# HC32F448 register map
File version: 1.0
CPU: CM4 r0p1, little endian, MPU, FPU, 4 interrupt priority bits
Registers are 32-bit, read-write, reset 0x0 unless marked. A register's access mark holds for its fields unless they carry their own. Offsets are from the block's base; [hi:lo] are bit positions; {n}, {i} and the like mark numbered series.

## TMR6CR
Base 0x4003C000; alternate view of TMR61
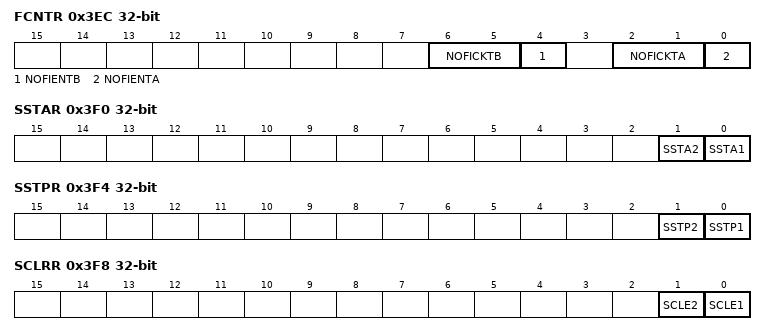
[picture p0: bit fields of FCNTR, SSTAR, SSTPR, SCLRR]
0x3EC FCNTR
  [6:5] NOFICKTB, [4] NOFIENTB, [2:1] NOFICKTA, [0] NOFIENTA
0x3F0 SSTAR
  [1] SSTA2, [0] SSTA1
0x3F4 SSTPR
  [1] SSTP2, [0] SSTP1
0x3F8 SCLRR
  [1] SCLE2, [0] SCLE1
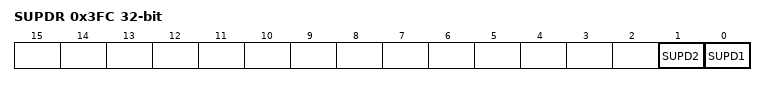
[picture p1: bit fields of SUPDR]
0x3FC SUPDR
  [1] SUPD2, [0] SUPD1

## TMRA1 — desc TMRA
Base 0x4003A000
Same registers: TMRA5 0x40026000, TMRA2 0x4003A400, TMRA3 0x4003A800, TMRA4 0x4003AC00
0x00 CNTER
  [31:0] CNT
0x04 PERAR reset 0xFFFFFFFF
  [31:0] PER
{0x3C+4i} CMPAR{i} reset 0xFFFFFFFF (i=1..8)
  [31:0] CMP
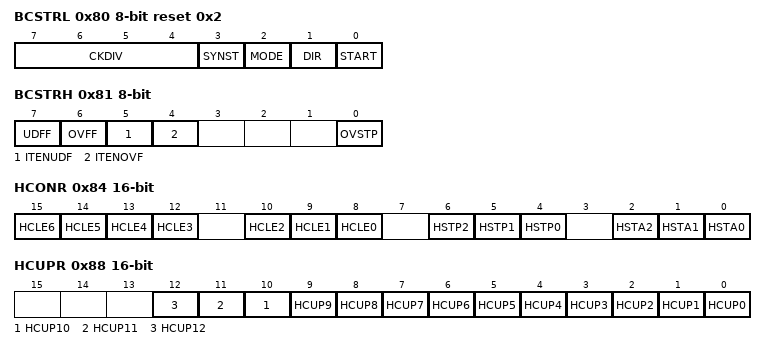
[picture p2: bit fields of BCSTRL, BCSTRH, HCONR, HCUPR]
0x80 BCSTRL 8-bit reset 0x2
  [7:4] CKDIV, [3] SYNST, [2] MODE, [1] DIR, [0] START
0x81 BCSTRH 8-bit
  [7] UDFF, [6] OVFF, [5] ITENUDF, [4] ITENOVF, [0] OVSTP
0x84 HCONR 16-bit
  [n+9] HCLE{n} (n=3..6), [10] HCLE2, [9] HCLE1, [8] HCLE0, [6] HSTP2, [5] HSTP1, [4] HSTP0, [2] HSTA2, [1] HSTA1, [0] HSTA0
0x88 HCUPR 16-bit
  [n] HCUP{n} (n=0..12)
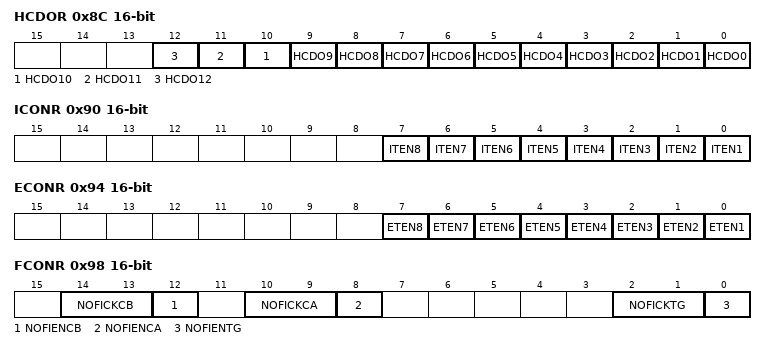
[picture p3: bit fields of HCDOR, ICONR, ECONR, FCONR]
0x8C HCDOR 16-bit
  [n] HCDO{n} (n=0..12)
0x90 ICONR 16-bit
  [n-1] ITEN{n} (n=1..8)
0x94 ECONR 16-bit
  [n-1] ETEN{n} (n=1..8)
0x98 FCONR 16-bit
  [14:13] NOFICKCB, [12] NOFIENCB, [10:9] NOFICKCA, [8] NOFIENCA, [2:1] NOFICKTG, [0] NOFIENTG
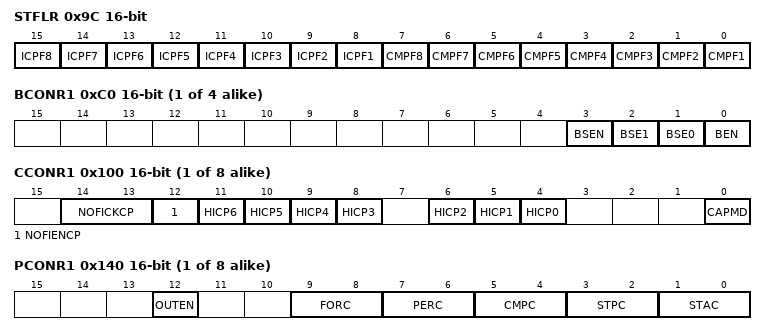
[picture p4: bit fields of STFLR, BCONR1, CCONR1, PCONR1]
0x9C STFLR 16-bit
  [n+7] ICPF{n} (n=1..8), [n-1] CMPF{n} (n=1..8)
{0xB8+8i} BCONR{i} 16-bit (i=1..4)
  [3] BSEN, [2] BSE1, [1] BSE0, [0] BEN
{0xFC+4i} CCONR{i} 16-bit (i=1..8)
  [14:13] NOFICKCP, [12] NOFIENCP, [n+5] HICP{n} (n=3..6), [6] HICP2, [5] HICP1, [4] HICP0, [0] CAPMD
{0x13C+4i} PCONR{i} 16-bit (i=1..8)
  [12] OUTEN, [9:8] FORC, [7:6] PERC, [5:4] CMPC, [3:2] STPC, [1:0] STAC

## TRNG
Base 0x40042000
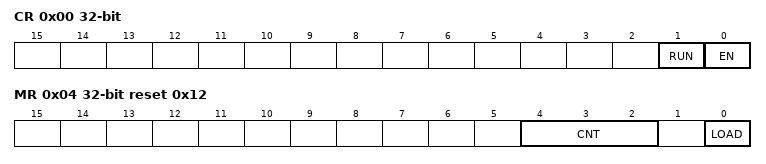
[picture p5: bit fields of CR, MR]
0x00 CR
  [1] RUN, [0] EN
0x04 MR reset 0x12
  [4:2] CNT, [0] LOAD
0x0C DR0 ro
0x10 DR1 ro

## USART1 — desc USART
Base 0x4001CC00
Same registers: USART2 0x4001D000, USART4 0x40020C00
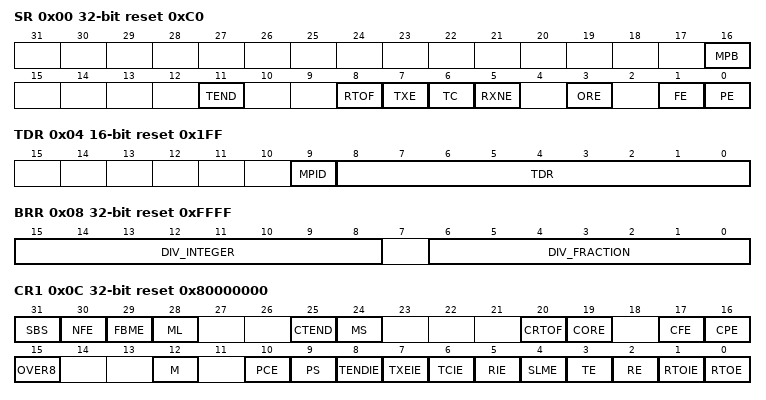
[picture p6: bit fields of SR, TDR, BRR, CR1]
0x00 SR ro reset 0xC0
  [16] MPB, [11] TEND, [8] RTOF, [7] TXE, [6] TC, [5] RXNE, [3] ORE, [1] FE, [0] PE
0x04 TDR 16-bit reset 0x1FF
  [9] MPID, [8:0] TDR
0x06 RDR 16-bit ro
  [8:0] RDR
0x08 BRR reset 0xFFFF
  [15:8] DIV_INTEGER, [6:0] DIV_FRACTION
0x0C CR1 reset 0x80000000
  [31] SBS, [30] NFE, [29] FBME, [28] ML, [25] CTEND, [24] MS, [20] CRTOF, [19] CORE, [17] CFE, [16] CPE, [15] OVER8, [12] M, [10] PCE, [9] PS, [8] TENDIE, [7] TXEIE, [6] TCIE, [5] RIE, [4] SLME, [3] TE, [2] RE, [1] RTOIE, [0] RTOE
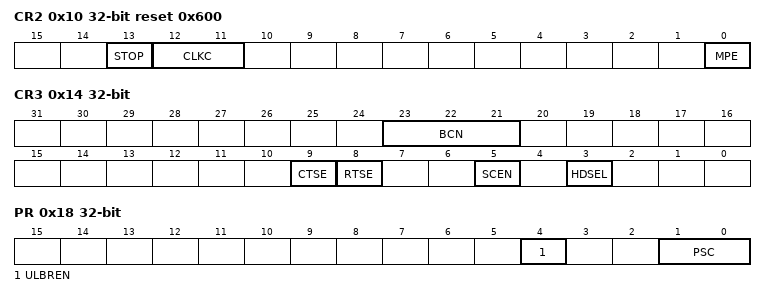
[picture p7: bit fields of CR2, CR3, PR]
0x10 CR2 reset 0x600
  [13] STOP, [12:11] CLKC, [0] MPE
0x14 CR3
  [23:21] BCN, [9] CTSE, [8] RTSE, [5] SCEN, [3] HDSEL
0x18 PR
  [4] ULBREN, [1:0] PSC

## USART5
Base 0x40021000
Registers as USART1; these are added or differ:
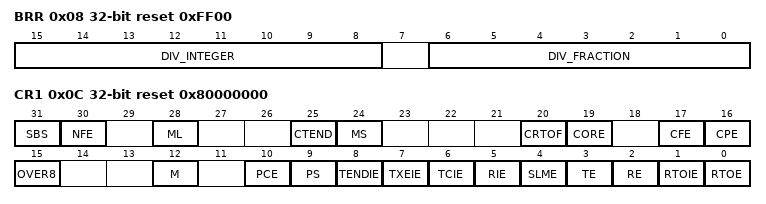
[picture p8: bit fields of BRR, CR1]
0x08 BRR reset 0xFF00
  [15:8] DIV_INTEGER, [6:0] DIV_FRACTION
0x0C CR1 reset 0x80000000
  [31] SBS, [30] NFE, [28] ML, [25] CTEND, [24] MS, [20] CRTOF, [19] CORE, [17] CFE, [16] CPE, [15] OVER8, [12] M, [10] PCE, [9] PS, [8] TENDIE, [7] TXEIE, [6] TCIE, [5] RIE, [4] SLME, [3] TE, [2] RE, [1] RTOIE, [0] RTOE

## USART3 — desc USART
Base 0x4001D400
Same registers: USART6 0x40021400
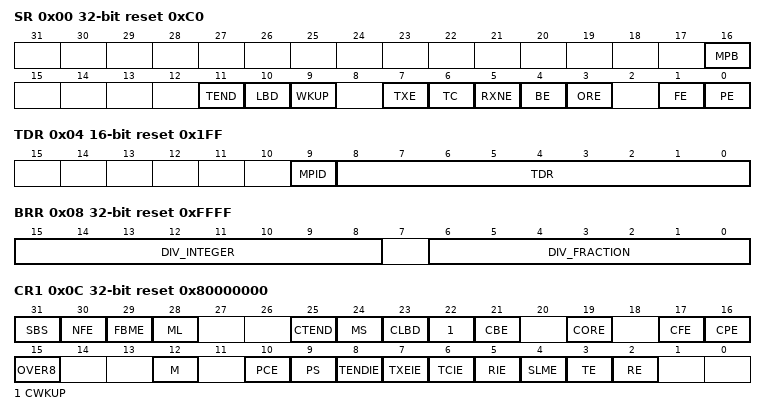
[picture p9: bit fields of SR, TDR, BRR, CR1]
0x00 SR ro reset 0xC0
  [16] MPB, [11] TEND, [10] LBD, [9] WKUP, [7] TXE, [6] TC, [5] RXNE, [4] BE, [3] ORE, [1] FE, [0] PE
0x04 TDR 16-bit reset 0x1FF
  [9] MPID, [8:0] TDR
0x06 RDR 16-bit ro
  [8:0] RDR
0x08 BRR reset 0xFFFF
  [15:8] DIV_INTEGER, [6:0] DIV_FRACTION
0x0C CR1 reset 0x80000000
  [31] SBS, [30] NFE, [29] FBME, [28] ML, [25] CTEND, [24] MS, [23] CLBD, [22] CWKUP, [21] CBE, [19] CORE, [17] CFE, [16] CPE, [15] OVER8, [12] M, [10] PCE, [9] PS, [8] TENDIE, [7] TXEIE, [6] TCIE, [5] RIE, [4] SLME, [3] TE, [2] RE
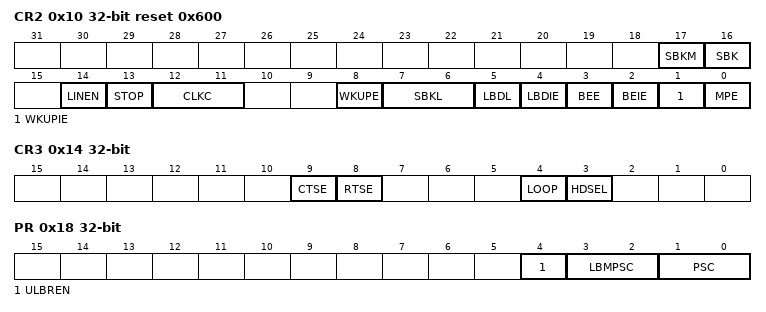
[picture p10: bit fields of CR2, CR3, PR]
0x10 CR2 reset 0x600
  [17] SBKM, [16] SBK, [14] LINEN, [13] STOP, [12:11] CLKC, [8] WKUPE, [7:6] SBKL, [5] LBDL, [4] LBDIE, [3] BEE, [2] BEIE, [1] WKUPIE, [0] MPE
0x14 CR3
  [9] CTSE, [8] RTSE, [4] LOOP, [3] HDSEL
0x18 PR
  [4] ULBREN, [3:2] LBMPSC, [1:0] PSC
0x1C LBMC ro
  [15:0] LBMC
